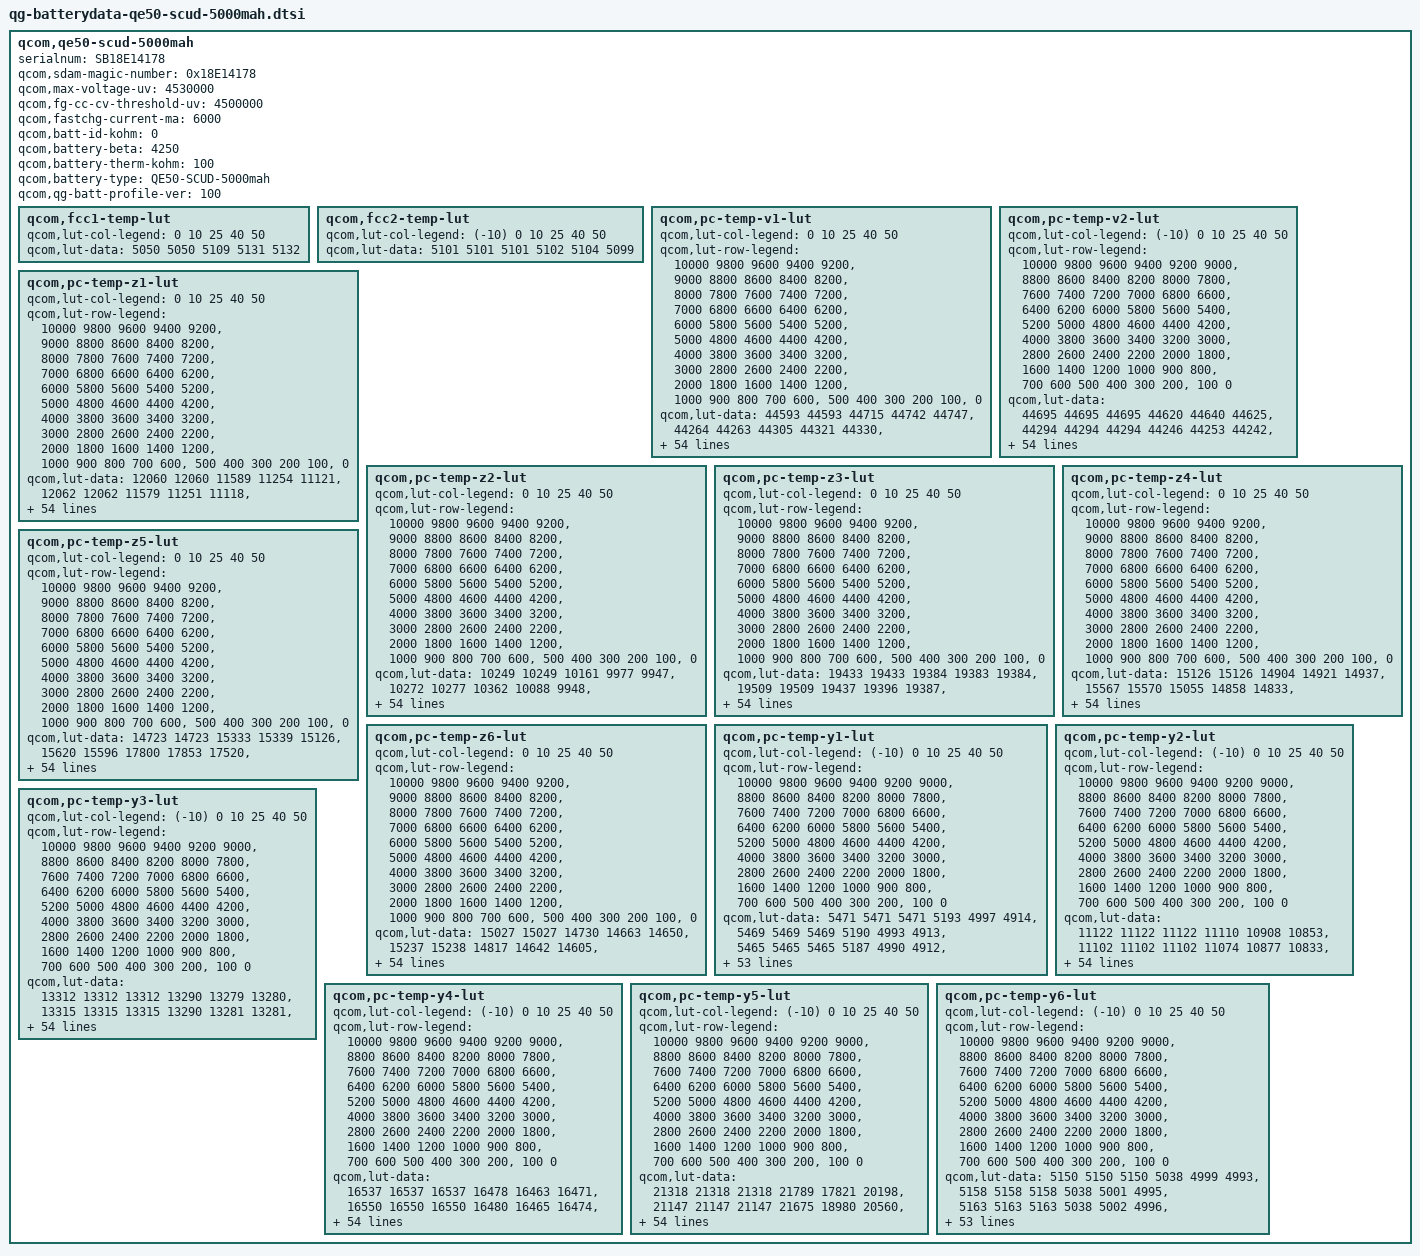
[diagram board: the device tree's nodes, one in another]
/* Copyright (c) 2018, The Linux Foundation. All rights reserved.
 *
 * This program is free software; you can redistribute it and/or modify
 * it under the terms of the GNU General Public License version 2 and
 * only version 2 as published by the Free Software Foundation.
 *
 * This program is distributed in the hope that it will be useful,
 * but WITHOUT ANY WARRANTY; without even the implied warranty of
 * MERCHANTABILITY or FITNESS FOR A PARTICULAR PURPOSE.  See the
 * GNU General Public License for more details.
 */

qcom,qe50-scud-5000mah {
    /* 6988512_Huaqin_QN6982A_5000mAH_averaged_MasterSlave_Jan24th2024 */
    serialnum = "SB18E14178";
    qcom,sdam-magic-number = <0x18E14178>;
    qcom,max-voltage-uv = <4530000>;
    qcom,fg-cc-cv-threshold-uv = <4500000>;
    qcom,fastchg-current-ma = <6000>;
    qcom,batt-id-kohm = <0>;
    qcom,battery-beta = <4250>;
    qcom,battery-therm-kohm = <100>;
    qcom,battery-type = "QE50-SCUD-5000mah";
    qcom,qg-batt-profile-ver = <100>;

	qcom,fcc1-temp-lut {
		qcom,lut-col-legend = <0 10 25 40 50>;
		qcom,lut-data = <5050 5050 5109 5131 5132>;
	};

	qcom,fcc2-temp-lut {
		qcom,lut-col-legend = <(-10) 0 10 25 40 50>;
		qcom,lut-data = <5101 5101 5101 5102 5104 5099>;
	};

	qcom,pc-temp-v1-lut {
		qcom,lut-col-legend = <0 10 25 40 50>;
		qcom,lut-row-legend = <10000 9800 9600 9400 9200>,
			<9000 8800 8600 8400 8200>,
			<8000 7800 7600 7400 7200>,
			<7000 6800 6600 6400 6200>,
			<6000 5800 5600 5400 5200>,
			<5000 4800 4600 4400 4200>,
			<4000 3800 3600 3400 3200>,
			<3000 2800 2600 2400 2200>,
			<2000 1800 1600 1400 1200>,
			<1000 900 800 700 600>,
			<500 400 300 200 100>,
			<0>;
		qcom,lut-data = <44593 44593 44715 44742 44747>,
			<44264 44263 44305 44321 44330>,
			<44034 44033 44047 44043 44049>,
			<43818 43818 43831 43825 43822>,
			<43593 43593 43611 43606 43601>,
			<43369 43369 43390 43385 43382>,
			<43135 43135 43164 43159 43160>,
			<42893 42893 42925 42924 42926>,
			<42647 42647 42679 42680 42683>,
			<42400 42400 42432 42436 42440>,
			<42152 42152 42183 42187 42198>,
			<41911 41911 41938 41943 41958>,
			<41676 41676 41697 41704 41719>,
			<41446 41446 41462 41469 41483>,
			<41221 41221 41238 41242 41253>,
			<41003 41003 41023 41019 41027>,
			<40795 40795 40814 40806 40810>,
			<40596 40596 40608 40602 40603>,
			<40407 40407 40410 40407 40406>,
			<40232 40232 40230 40228 40223>,
			<40059 40059 40062 40062 40058>,
			<39873 39873 39876 39871 39871>,
			<39680 39680 39659 39622 39622>,
			<39470 39470 39438 39374 39370>,
			<39211 39211 39225 39184 39187>,
			<38980 38980 39023 39023 39038>,
			<38855 38855 38881 38889 38905>,
			<38769 38769 38783 38780 38782>,
			<38685 38685 38694 38681 38672>,
			<38597 38597 38600 38583 38576>,
			<38514 38514 38510 38491 38491>,
			<38439 38439 38428 38410 38411>,
			<38370 38370 38353 38338 38337>,
			<38308 38308 38285 38270 38265>,
			<38254 38254 38228 38205 38196>,
			<38205 38205 38174 38142 38128>,
			<38161 38161 38120 38077 38059>,
			<38119 38119 38066 38013 37989>,
			<38064 38064 38001 37935 37904>,
			<37988 37988 37919 37829 37784>,
			<37894 37894 37819 37710 37648>,
			<37778 37778 37705 37597 37528>,
			<37636 37636 37570 37478 37408>,
			<37469 37469 37407 37314 37243>,
			<37306 37306 37246 37161 37091>,
			<37174 37174 37129 37069 37006>,
			<37127 37127 37088 37039 36982>,
			<37102 37101 37059 37014 36961>,
			<37072 37072 37032 36989 36934>,
			<37038 37038 36999 36951 36889>,
			<36914 36914 36854 36751 36669>,
			<36515 36515 36439 36333 36241>,
			<35917 35917 35854 35760 35667>,
			<35071 35071 35052 34975 34881>,
			<33684 33684 33799 33761 33662>,
			<30000 30000 30000 30000 30000>;
	};

	qcom,pc-temp-v2-lut {
		qcom,lut-col-legend = <(-10) 0 10 25 40 50>;
		qcom,lut-row-legend = <10000 9800 9600 9400 9200 9000>,
			<8800 8600 8400 8200 8000 7800>,
			<7600 7400 7200 7000 6800 6600>,
			<6400 6200 6000 5800 5600 5400>,
			<5200 5000 4800 4600 4400 4200>,
			<4000 3800 3600 3400 3200 3000>,
			<2800 2600 2400 2200 2000 1800>,
			<1600 1400 1200 1000 900 800>,
			<700 600 500 400 300 200>,
			<100 0>;
		qcom,lut-data = <44695 44695 44695 44620 44640 44625>,
			<44294 44294 44294 44246 44253 44242>,
			<43951 43951 43951 43921 43919 43911>,
			<43681 43681 43681 43656 43652 43644>,
			<43468 43468 43468 43441 43439 43429>,
			<43254 43254 43254 43224 43224 43213>,
			<43021 43021 43021 42989 42992 42982>,
			<42782 42782 42782 42750 42755 42747>,
			<42537 42537 42537 42507 42511 42507>,
			<42285 42285 42285 42259 42260 42262>,
			<42036 42036 42036 42013 42012 42018>,
			<41792 41792 41792 41770 41771 41776>,
			<41551 41551 41551 41530 41534 41537>,
			<41314 41314 41314 41296 41300 41302>,
			<41082 41082 41082 41067 41071 41073>,
			<40859 40859 40859 40846 40850 40852>,
			<40643 40643 40643 40633 40637 40637>,
			<40437 40437 40437 40428 40433 40431>,
			<40253 40253 40253 40235 40240 40235>,
			<40076 40076 40076 40050 40055 40048>,
			<39863 39863 39863 39859 39876 39869>,
			<39594 39594 39594 39666 39707 39706>,
			<39334 39334 39334 39461 39522 39527>,
			<39112 39112 39112 39216 39270 39280>,
			<38913 38913 38913 38966 39001 39011>,
			<38747 38747 38747 38785 38815 38824>,
			<38604 38604 38604 38647 38680 38690>,
			<38477 38477 38477 38528 38562 38572>,
			<38362 38362 38362 38420 38451 38458>,
			<38258 38258 38258 38323 38351 38355>,
			<38162 38162 38162 38232 38263 38264>,
			<38073 38073 38073 38147 38184 38182>,
			<37994 37994 37994 38070 38109 38107>,
			<37923 37923 37923 38002 38040 38043>,
			<37858 37858 37858 37935 37972 37980>,
			<37805 37805 37805 37862 37898 37897>,
			<37759 37759 37759 37786 37819 37799>,
			<37705 37705 37705 37706 37730 37694>,
			<37638 37638 37638 37626 37626 37584>,
			<37558 37558 37558 37540 37517 37473>,
			<37460 37460 37460 37448 37423 37376>,
			<37340 37340 37340 37345 37328 37279>,
			<37197 37197 37197 37220 37213 37166>,
			<37033 37033 37033 37078 37070 37024>,
			<36843 36843 36843 36942 36933 36882>,
			<36734 36734 36734 36864 36870 36824>,
			<36688 36688 36688 36850 36857 36812>,
			<36641 36641 36641 36833 36843 36798>,
			<36581 36581 36581 36808 36822 36775>,
			<36485 36485 36485 36744 36774 36717>,
			<36254 36254 36254 36513 36557 36467>,
			<35705 35705 35705 36021 36085 35992>,
			<34900 34900 34900 35344 35451 35349>,
			<33903 33903 33903 34392 34563 34450>,
			<32653 32653 32653 33093 33222 33072>,
			<28765 28765 28765 28469 28654 28712>;
	};

	qcom,pc-temp-z1-lut {
		qcom,lut-col-legend = <0 10 25 40 50>;
		qcom,lut-row-legend = <10000 9800 9600 9400 9200>,
			<9000 8800 8600 8400 8200>,
			<8000 7800 7600 7400 7200>,
			<7000 6800 6600 6400 6200>,
			<6000 5800 5600 5400 5200>,
			<5000 4800 4600 4400 4200>,
			<4000 3800 3600 3400 3200>,
			<3000 2800 2600 2400 2200>,
			<2000 1800 1600 1400 1200>,
			<1000 900 800 700 600>,
			<500 400 300 200 100>,
			<0>;
		qcom,lut-data = <12060 12060 11589 11254 11121>,
			<12062 12062 11579 11251 11118>,
			<12049 12049 11572 11239 11113>,
			<12035 12035 11559 11231 11106>,
			<12017 12017 11545 11224 11100>,
			<11994 11994 11530 11216 11095>,
			<11970 11970 11517 11209 11091>,
			<11944 11944 11506 11204 11087>,
			<11924 11924 11496 11201 11084>,
			<11910 11910 11491 11197 11082>,
			<11900 11900 11488 11195 11080>,
			<11895 11895 11486 11192 11079>,
			<11890 11890 11481 11190 11078>,
			<11885 11885 11476 11188 11077>,
			<11881 11881 11474 11188 11076>,
			<11876 11876 11472 11189 11076>,
			<11875 11875 11472 11190 11075>,
			<11876 11876 11472 11188 11076>,
			<11877 11877 11472 11186 11076>,
			<11881 11881 11472 11186 11077>,
			<11885 11885 11472 11188 11078>,
			<11886 11886 11473 11189 11079>,
			<11886 11886 11474 11189 11079>,
			<11887 11887 11476 11188 11079>,
			<11898 11898 11479 11189 11079>,
			<11911 11911 11484 11192 11080>,
			<11912 11912 11488 11194 11082>,
			<11911 11911 11490 11196 11083>,
			<11911 11911 11494 11199 11085>,
			<11920 11920 11500 11202 11088>,
			<11930 11930 11507 11205 11092>,
			<11932 11932 11511 11209 11095>,
			<11932 11932 11513 11212 11098>,
			<11934 11934 11516 11216 11101>,
			<11941 11941 11521 11220 11104>,
			<11950 11950 11529 11226 11108>,
			<11956 11956 11535 11231 11112>,
			<11961 11961 11542 11236 11116>,
			<11968 11968 11549 11241 11120>,
			<11978 11978 11557 11245 11124>,
			<11988 11988 11565 11250 11127>,
			<12000 12000 11572 11255 11131>,
			<12015 12015 11580 11261 11135>,
			<12030 12030 11588 11266 11138>,
			<12033 12033 11600 11271 11142>,
			<12032 12032 11606 11273 11145>,
			<12052 12052 11602 11273 11144>,
			<12034 12034 11605 11274 11146>,
			<12049 12049 11613 11276 11148>,
			<12045 12045 11619 11282 11152>,
			<12063 12063 11637 11289 11159>,
			<12073 12073 11643 11298 11166>,
			<12100 12100 11660 11312 11179>,
			<12120 12120 11693 11333 11200>,
			<12120 12120 11693 11333 11200>,
			<12120 12120 11693 11333 11200>;
	};

	qcom,pc-temp-z2-lut {
		qcom,lut-col-legend = <0 10 25 40 50>;
		qcom,lut-row-legend = <10000 9800 9600 9400 9200>,
			<9000 8800 8600 8400 8200>,
			<8000 7800 7600 7400 7200>,
			<7000 6800 6600 6400 6200>,
			<6000 5800 5600 5400 5200>,
			<5000 4800 4600 4400 4200>,
			<4000 3800 3600 3400 3200>,
			<3000 2800 2600 2400 2200>,
			<2000 1800 1600 1400 1200>,
			<1000 900 800 700 600>,
			<500 400 300 200 100>,
			<0>;
		qcom,lut-data = <10249 10249 10161 9977 9947>,
			<10272 10277 10362 10088 9948>,
			<10322 10324 10364 10197 10022>,
			<10343 10343 10332 10196 10147>,
			<10322 10322 10297 10192 10197>,
			<10284 10284 10253 10182 10161>,
			<10256 10256 10214 10168 10125>,
			<10233 10233 10180 10140 10120>,
			<10215 10215 10154 10101 10105>,
			<10198 10198 10151 10092 10087>,
			<10186 10186 10163 10101 10042>,
			<10187 10187 10175 10110 10007>,
			<10201 10201 10183 10105 10005>,
			<10216 10216 10190 10091 10007>,
			<10228 10228 10310 10082 10014>,
			<10240 10240 10760 10059 10040>,
			<10250 10250 10977 10047 10061>,
			<10259 10259 10639 10042 10051>,
			<10267 10267 10245 10036 10030>,
			<10275 10275 10209 10037 10031>,
			<10284 10284 10208 10043 10041>,
			<10299 10299 10215 10062 10062>,
			<10321 10321 10271 10250 10265>,
			<10332 10332 10319 10441 10494>,
			<10334 10334 10296 10368 10435>,
			<10334 10334 10244 10158 10191>,
			<10327 10327 10227 10109 10113>,
			<10313 10313 10230 10288 10365>,
			<10307 10307 10235 10433 10595>,
			<10307 10307 10248 10366 10475>,
			<10308 10308 10263 10220 10187>,
			<10308 10308 10261 10128 10046>,
			<10309 10309 10235 10060 9981>,
			<10311 10311 10217 10027 9953>,
			<10319 10319 10213 10019 9956>,
			<10329 10329 10211 10016 9967>,
			<10340 10340 10220 10027 9987>,
			<10353 10353 10253 10067 10034>,
			<10364 10364 10279 10107 10083>,
			<10375 10375 10297 10144 10135>,
			<10382 10382 10310 10170 10175>,
			<10384 10384 10319 10172 10175>,
			<10385 10385 10324 10169 10165>,
			<10384 10384 10329 10181 10166>,
			<10415 10415 10336 10186 10169>,
			<10466 10466 10330 10188 10158>,
			<10460 10460 10309 10169 10135>,
			<10482 10480 10308 10181 10126>,
			<10529 10529 10313 10189 10150>,
			<10888 10887 10343 10242 10202>,
			<10869 10893 10348 10204 10172>,
			<10458 10459 10325 10114 10039>,
			<10377 10377 10301 10071 9986>,
			<10298 10298 10219 10023 9940>,
			<10298 10298 10219 10023 9940>,
			<10298 10298 10219 10023 9940>;
	};

	qcom,pc-temp-z3-lut {
		qcom,lut-col-legend = <0 10 25 40 50>;
		qcom,lut-row-legend = <10000 9800 9600 9400 9200>,
			<9000 8800 8600 8400 8200>,
			<8000 7800 7600 7400 7200>,
			<7000 6800 6600 6400 6200>,
			<6000 5800 5600 5400 5200>,
			<5000 4800 4600 4400 4200>,
			<4000 3800 3600 3400 3200>,
			<3000 2800 2600 2400 2200>,
			<2000 1800 1600 1400 1200>,
			<1000 900 800 700 600>,
			<500 400 300 200 100>,
			<0>;
		qcom,lut-data = <19433 19433 19384 19383 19384>,
			<19509 19509 19437 19396 19387>,
			<19522 19522 19444 19415 19407>,
			<19526 19526 19444 19415 19411>,
			<19528 19528 19443 19415 19413>,
			<19529 19530 19441 19419 19415>,
			<19529 19529 19439 19423 19416>,
			<19525 19525 19438 19421 19416>,
			<19521 19521 19437 19418 19415>,
			<19518 19518 19436 19415 19413>,
			<19514 19514 19433 19414 19409>,
			<19509 19509 19430 19412 19404>,
			<19500 19500 19427 19409 19401>,
			<19493 19493 19425 19405 19399>,
			<19490 19490 19425 19402 19397>,
			<19488 19488 19428 19398 19395>,
			<19485 19485 19429 19395 19392>,
			<19482 19482 19422 19392 19389>,
			<19479 19479 19412 19388 19385>,
			<19475 19475 19407 19383 19380>,
			<19472 19472 19403 19377 19373>,
			<19473 19473 19403 19375 19371>,
			<19476 19476 19410 19385 19376>,
			<19479 19479 19416 19395 19383>,
			<19482 19482 19412 19389 19378>,
			<19484 19484 19405 19373 19362>,
			<19482 19482 19403 19370 19358>,
			<19477 19477 19405 19395 19395>,
			<19475 19475 19408 19416 19429>,
			<19478 19478 19415 19416 19427>,
			<19481 19481 19423 19415 19416>,
			<19482 19482 19425 19412 19407>,
			<19482 19482 19423 19404 19399>,
			<19481 19481 19420 19395 19391>,
			<19479 19479 19415 19387 19382>,
			<19475 19475 19409 19379 19372>,
			<19473 19473 19404 19372 19364>,
			<19470 19470 19400 19365 19355>,
			<19467 19467 19397 19362 19351>,
			<19463 19463 19395 19365 19353>,
			<19459 19459 19394 19368 19356>,
			<19456 19456 19391 19366 19358>,
			<19453 19453 19387 19363 19360>,
			<19450 19450 19386 19365 19362>,
			<19438 19438 19384 19365 19362>,
			<19425 19425 19377 19360 19356>,
			<19425 19425 19374 19355 19353>,
			<19392 19403 19368 19345 19342>,
			<19368 19369 19366 19342 19336>,
			<19323 19323 19359 19333 19325>,
			<19327 19324 19361 19346 19332>,
			<19391 19390 19377 19359 19348>,
			<19424 19424 19379 19360 19350>,
			<19443 19443 19379 19362 19350>,
			<19443 19443 19379 19362 19350>,
			<19443 19443 19379 19362 19350>;
	};

	qcom,pc-temp-z4-lut {
		qcom,lut-col-legend = <0 10 25 40 50>;
		qcom,lut-row-legend = <10000 9800 9600 9400 9200>,
			<9000 8800 8600 8400 8200>,
			<8000 7800 7600 7400 7200>,
			<7000 6800 6600 6400 6200>,
			<6000 5800 5600 5400 5200>,
			<5000 4800 4600 4400 4200>,
			<4000 3800 3600 3400 3200>,
			<3000 2800 2600 2400 2200>,
			<2000 1800 1600 1400 1200>,
			<1000 900 800 700 600>,
			<500 400 300 200 100>,
			<0>;
		qcom,lut-data = <15126 15126 14904 14921 14937>,
			<15567 15570 15055 14858 14833>,
			<15325 15326 15043 14921 14908>,
			<15100 15100 14927 14857 14851>,
			<15000 15000 14859 14809 14806>,
			<14928 14928 14822 14782 14783>,
			<14875 14875 14793 14762 14765>,
			<14834 14834 14768 14745 14751>,
			<14802 14802 14748 14731 14740>,
			<14775 14775 14734 14724 14736>,
			<14753 14753 14723 14720 14735>,
			<14740 14740 14715 14717 14734>,
			<14731 14731 14710 14714 14731>,
			<14723 14723 14706 14711 14728>,
			<14717 14717 14697 14708 14724>,
			<14713 14713 14678 14705 14722>,
			<14709 14709 14669 14703 14719>,
			<14707 14707 14679 14700 14717>,
			<14704 14704 14690 14697 14715>,
			<14700 14700 14688 14691 14710>,
			<14697 14697 14682 14681 14697>,
			<14698 14698 14682 14679 14692>,
			<14708 14708 14702 14709 14725>,
			<14724 14724 14731 14752 14773>,
			<14775 14775 14766 14783 14799>,
			<14823 14823 14805 14811 14819>,
			<14820 14820 14811 14814 14820>,
			<14799 14799 14790 14769 14768>,
			<14779 14779 14765 14726 14717>,
			<14762 14762 14743 14714 14710>,
			<14747 14747 14723 14707 14707>,
			<14736 14736 14713 14701 14703>,
			<14728 14728 14707 14695 14697>,
			<14723 14723 14702 14690 14691>,
			<14719 14719 14698 14684 14684>,
			<14716 14716 14694 14679 14678>,
			<14713 14713 14690 14675 14674>,
			<14709 14709 14687 14672 14671>,
			<14705 14705 14686 14672 14670>,
			<14701 14701 14686 14681 14684>,
			<14695 14695 14686 14691 14701>,
			<14688 14688 14684 14689 14699>,
			<14678 14678 14678 14682 14690>,
			<14670 14670 14673 14684 14696>,
			<14657 14657 14663 14681 14698>,
			<14642 14642 14645 14655 14664>,
			<14638 14638 14641 14649 14655>,
			<14665 14652 14636 14644 14646>,
			<14684 14683 14625 14630 14631>,
			<14731 14731 14620 14617 14618>,
			<14724 14727 14623 14635 14654>,
			<14668 14668 14633 14662 14684>,
			<14643 14643 14640 14672 14697>,
			<14652 14652 14648 14677 14703>,
			<14652 14652 14648 14677 14703>,
			<14652 14652 14648 14677 14703>;
	};

	qcom,pc-temp-z5-lut {
		qcom,lut-col-legend = <0 10 25 40 50>;
		qcom,lut-row-legend = <10000 9800 9600 9400 9200>,
			<9000 8800 8600 8400 8200>,
			<8000 7800 7600 7400 7200>,
			<7000 6800 6600 6400 6200>,
			<6000 5800 5600 5400 5200>,
			<5000 4800 4600 4400 4200>,
			<4000 3800 3600 3400 3200>,
			<3000 2800 2600 2400 2200>,
			<2000 1800 1600 1400 1200>,
			<1000 900 800 700 600>,
			<500 400 300 200 100>,
			<0>;
		qcom,lut-data = <14723 14723 15333 15339 15126>,
			<15620 15596 17800 17853 17520>,
			<16709 16697 18072 18923 18117>,
			<17877 17878 19365 20293 21017>,
			<18936 18941 20156 21689 23402>,
			<19971 19979 20595 23202 24814>,
			<20875 20882 21066 24635 26080>,
			<21640 21644 21810 25753 27606>,
			<22495 22495 22731 26709 29261>,
			<23777 23776 23693 27613 29677>,
			<25097 25097 24872 28559 29047>,
			<25778 25778 26005 29287 28486>,
			<26140 26140 26872 29838 28764>,
			<26620 26620 27747 30286 29583>,
			<27640 27640 29680 30513 30587>,
			<28880 28880 33651 31541 32094>,
			<29798 29798 35411 32209 33462>,
			<30539 30539 33522 32666 34346>,
			<31236 31236 31262 33233 35124>,
			<31887 31887 31003 33339 35906>,
			<32728 32728 31383 33364 36912>,
			<34937 34937 32337 33714 37950>,
			<39087 39087 36368 40690 41336>,
			<40773 40773 39682 47861 45007>,
			<39512 39513 35940 41779 40264>,
			<37268 37268 27689 25796 25284>,
			<34070 34066 24377 20982 20130>,
			<29715 29702 23270 23985 28941>,
			<28268 28253 22833 27629 37098>,
			<29448 29440 24823 30543 36829>,
			<31361 31360 28836 33072 35504>,
			<33576 33578 31863 33485 34878>,
			<36368 36368 34548 33244 34691>,
			<38360 38360 36035 33035 34448>,
			<39848 39848 36442 32694 33508>,
			<41130 41130 36733 32285 32096>,
			<42456 42456 37314 32282 31256>,
			<43818 43818 38196 32591 30557>,
			<44153 44153 38809 33244 30551>,
			<43890 43890 39199 37778 34313>,
			<43459 43459 39434 42474 38661>,
			<42620 42620 37990 39787 38263>,
			<41827 41827 34995 33587 36260>,
			<42045 42045 36281 36670 38895>,
			<40359 40359 39150 40422 41777>,
			<38031 38031 37650 38296 41191>,
			<38892 38892 34512 31252 34532>,
			<20589 23110 30161 24405 24367>,
			<15962 16019 32244 27414 25944>,
			<13046 13048 30265 28185 28365>,
			<13162 13053 30438 43929 33162>,
			<23729 23723 36887 27397 22087>,
			<31434 31435 33541 21834 18063>,
			<40625 40625 27548 18799 15647>,
			<40625 40625 27548 18799 15647>,
			<40625 40625 27548 18799 15647>;
	};

	qcom,pc-temp-z6-lut {
		qcom,lut-col-legend = <0 10 25 40 50>;
		qcom,lut-row-legend = <10000 9800 9600 9400 9200>,
			<9000 8800 8600 8400 8200>,
			<8000 7800 7600 7400 7200>,
			<7000 6800 6600 6400 6200>,
			<6000 5800 5600 5400 5200>,
			<5000 4800 4600 4400 4200>,
			<4000 3800 3600 3400 3200>,
			<3000 2800 2600 2400 2200>,
			<2000 1800 1600 1400 1200>,
			<1000 900 800 700 600>,
			<500 400 300 200 100>,
			<0>;
		qcom,lut-data = <15027 15027 14730 14663 14650>,
			<15237 15238 14817 14642 14605>,
			<15123 15123 14812 14678 14645>,
			<15013 15013 14757 14647 14622>,
			<14960 14960 14723 14626 14603>,
			<14919 14919 14702 14616 14594>,
			<14886 14886 14685 14607 14587>,
			<14857 14857 14672 14598 14581>,
			<14834 14834 14660 14590 14575>,
			<14813 14813 14651 14585 14570>,
			<14797 14797 14644 14582 14567>,
			<14783 14783 14638 14579 14564>,
			<14773 14773 14633 14575 14561>,
			<14765 14765 14630 14571 14558>,
			<14759 14759 14625 14568 14555>,
			<14755 14755 14620 14564 14553>,
			<14752 14752 14617 14561 14550>,
			<14749 14749 14615 14558 14547>,
			<14746 14746 14614 14555 14544>,
			<14742 14742 14611 14549 14539>,
			<14740 14740 14607 14542 14530>,
			<14741 14741 14606 14540 14526>,
			<14748 14748 14618 14559 14545>,
			<14759 14759 14634 14583 14569>,
			<14784 14784 14649 14591 14574>,
			<14806 14806 14662 14596 14575>,
			<14805 14805 14664 14596 14576>,
			<14795 14795 14657 14592 14574>,
			<14788 14788 14650 14586 14571>,
			<14784 14784 14645 14582 14567>,
			<14780 14780 14642 14578 14561>,
			<14777 14777 14639 14573 14555>,
			<14774 14774 14636 14568 14549>,
			<14772 14772 14634 14561 14542>,
			<14770 14770 14630 14555 14535>,
			<14768 14768 14626 14549 14527>,
			<14768 14768 14624 14544 14521>,
			<14767 14767 14621 14540 14515>,
			<14767 14767 14621 14538 14513>,
			<14766 14766 14622 14544 14520>,
			<14766 14766 14623 14550 14529>,
			<14765 14765 14622 14549 14529>,
			<14764 14764 14619 14545 14526>,
			<14765 14765 14619 14548 14530>,
			<14761 14761 14616 14547 14531>,
			<14753 14753 14607 14534 14514>,
			<14752 14752 14604 14529 14509>,
			<14747 14747 14599 14522 14500>,
			<14745 14745 14595 14514 14491>,
			<14746 14746 14591 14505 14479>,
			<14751 14751 14596 14520 14499>,
			<14766 14766 14613 14541 14524>,
			<14782 14782 14622 14549 14533>,
			<14809 14809 14633 14557 14542>,
			<14809 14809 14633 14557 14542>,
			<14809 14809 14633 14557 14542>;
	};

	qcom,pc-temp-y1-lut {
		qcom,lut-col-legend = <(-10) 0 10 25 40 50>;
		qcom,lut-row-legend = <10000 9800 9600 9400 9200 9000>,
			<8800 8600 8400 8200 8000 7800>,
			<7600 7400 7200 7000 6800 6600>,
			<6400 6200 6000 5800 5600 5400>,
			<5200 5000 4800 4600 4400 4200>,
			<4000 3800 3600 3400 3200 3000>,
			<2800 2600 2400 2200 2000 1800>,
			<1600 1400 1200 1000 900 800>,
			<700 600 500 400 300 200>,
			<100 0>;
		qcom,lut-data = <5471 5471 5471 5193 4997 4914>,
			<5469 5469 5469 5190 4993 4913>,
			<5465 5465 5465 5187 4990 4912>,
			<5461 5461 5461 5183 4987 4910>,
			<5457 5457 5457 5179 4984 4909>,
			<5455 5455 5455 5176 4982 4907>,
			<5451 5451 5451 5171 4980 4906>,
			<5449 5449 5449 5167 4978 4904>,
			<5449 5449 5449 5164 4975 4903>,
			<5453 5453 5453 5162 4973 4902>,
			<5454 5454 5454 5160 4972 4902>,
			<5448 5448 5448 5158 4970 4901>,
			<5441 5441 5441 5155 4969 4901>,
			<5440 5440 5440 5153 4968 4901>,
			<5441 5441 5441 5151 4967 4900>,
			<5441 5441 5441 5150 4967 4900>,
			<5441 5441 5441 5149 4967 4900>,
			<5441 5441 5441 5148 4967 4900>,
			<5439 5439 5439 5146 4967 4900>,
			<5436 5436 5436 5145 4967 4900>,
			<5437 5437 5437 5145 4968 4901>,
			<5444 5444 5444 5147 4969 4901>,
			<5449 5449 5449 5149 4969 4902>,
			<5446 5446 5446 5153 4970 4902>,
			<5442 5442 5442 5158 4971 4903>,
			<5443 5443 5443 5160 4972 4904>,
			<5450 5450 5450 5161 4974 4905>,
			<5455 5455 5455 5162 4976 4906>,
			<5456 5456 5456 5163 4978 4908>,
			<5455 5455 5455 5165 4980 4909>,
			<5456 5456 5456 5168 4982 4911>,
			<5460 5460 5460 5173 4984 4913>,
			<5461 5461 5461 5177 4986 4914>,
			<5458 5458 5458 5182 4988 4916>,
			<5455 5455 5455 5185 4990 4918>,
			<5458 5458 5458 5186 4992 4919>,
			<5469 5469 5469 5187 4993 4920>,
			<5474 5474 5474 5188 4994 4921>,
			<5474 5474 5474 5191 4995 4921>,
			<5475 5475 5475 5194 4995 4922>,
			<5477 5477 5477 5195 4997 4923>,
			<5482 5482 5482 5195 4998 4925>,
			<5489 5489 5489 5199 5000 4926>,
			<5493 5493 5493 5206 5002 4928>,
			<5496 5496 5496 5213 5006 4931>,
			<5503 5503 5503 5220 5010 4933>,
			<5500 5500 5500 5226 5009 4934>,
			<5526 5526 5526 5228 5009 4933>,
			<5512 5512 5512 5225 5009 4934>,
			<5511 5511 5511 5228 5010 4935>,
			<5565 5565 5565 5231 5012 4937>,
			<5585 5585 5585 5240 5017 4941>,
			<5655 5655 5655 5266 5024 4948>,
			<5692 5692 5692 5305 5034 4959>,
			<5692 5692 5692 5305 5034 4959>,
			<5692 5692 5692 5305 5034 4959>;
	};

	qcom,pc-temp-y2-lut {
		qcom,lut-col-legend = <(-10) 0 10 25 40 50>;
		qcom,lut-row-legend = <10000 9800 9600 9400 9200 9000>,
			<8800 8600 8400 8200 8000 7800>,
			<7600 7400 7200 7000 6800 6600>,
			<6400 6200 6000 5800 5600 5400>,
			<5200 5000 4800 4600 4400 4200>,
			<4000 3800 3600 3400 3200 3000>,
			<2800 2600 2400 2200 2000 1800>,
			<1600 1400 1200 1000 900 800>,
			<700 600 500 400 300 200>,
			<100 0>;
		qcom,lut-data = <11122 11122 11122 11110 10908 10853>,
			<11102 11102 11102 11074 10877 10833>,
			<11080 11080 11080 11035 10843 10812>,
			<11055 11055 11055 10997 10812 10790>,
			<11030 11030 11030 10963 10786 10769>,
			<11002 11002 11002 10937 10768 10748>,
			<10972 10972 10972 10916 10759 10727>,
			<10942 10942 10942 10897 10750 10707>,
			<10912 10912 10912 10875 10733 10687>,
			<10883 10883 10883 10843 10704 10667>,
			<10864 10864 10864 10820 10684 10654>,
			<10852 10852 10852 10807 10672 10642>,
			<10845 10845 10845 10796 10664 10630>,
			<10852 10852 10852 10790 10659 10618>,
			<10876 10876 10876 10784 10654 10600>,
			<10907 10907 10907 10783 10650 10592>,
			<10952 10952 10952 10803 10642 10587>,
			<11006 11006 11006 10836 10636 10584>,
			<11072 11072 11072 10884 10654 10588>,
			<11140 11140 11140 10952 10706 10599>,
			<11152 11152 11152 11015 10779 10628>,
			<11130 11130 11130 11085 10916 10755>,
			<11110 11110 11110 11122 11000 10846>,
			<11105 11105 11105 11085 10941 10841>,
			<11102 11102 11102 11020 10846 10830>,
			<11103 11103 11103 10997 10833 10827>,
			<11116 11116 11116 10987 10855 10828>,
			<11132 11132 11132 10987 10872 10830>,
			<11151 11151 11151 11010 10892 10848>,
			<11168 11168 11168 11045 10915 10879>,
			<11178 11178 11178 11071 10918 10910>,
			<11184 11184 11184 11095 10918 10948>,
			<11187 11187 11187 11114 10924 10969>,
			<11181 11181 11181 11132 10963 10980>,
			<11171 11171 11171 11145 11002 10986>,
			<11159 11159 11159 11140 10994 10984>,
			<11140 11140 11140 11123 10960 10970>,
			<11111 11111 11111 11112 10937 10956>,
			<11051 11051 11051 11110 10925 10944>,
			<10972 10972 10972 11108 10916 10933>,
			<10887 10887 10887 11088 10919 10904>,
			<10786 10786 10786 11063 10928 10861>,
			<10667 10667 10667 11070 10913 10853>,
			<10497 10497 10497 11035 10889 10836>,
			<10019 10019 10019 11002 10897 10777>,
			<9946 9946 9946 10936 10785 10661>,
			<9811 9811 9811 10934 10743 10641>,
			<9707 9707 9707 10955 10749 10638>,
			<9673 9673 9673 10994 10747 10674>,
			<9660 9660 9660 11017 10800 10632>,
			<9654 9654 9654 10960 10755 10683>,
			<9651 9651 9651 10858 10696 10596>,
			<9650 9650 9650 10759 10623 10512>,
			<9650 9650 9650 10618 10500 10378>,
			<9650 9650 9650 10618 10500 10378>,
			<9650 9650 9650 10618 10500 10378>;
	};

	qcom,pc-temp-y3-lut {
		qcom,lut-col-legend = <(-10) 0 10 25 40 50>;
		qcom,lut-row-legend = <10000 9800 9600 9400 9200 9000>,
			<8800 8600 8400 8200 8000 7800>,
			<7600 7400 7200 7000 6800 6600>,
			<6400 6200 6000 5800 5600 5400>,
			<5200 5000 4800 4600 4400 4200>,
			<4000 3800 3600 3400 3200 3000>,
			<2800 2600 2400 2200 2000 1800>,
			<1600 1400 1200 1000 900 800>,
			<700 600 500 400 300 200>,
			<100 0>;
		qcom,lut-data = <13312 13312 13312 13290 13279 13280>,
			<13315 13315 13315 13290 13281 13281>,
			<13317 13317 13317 13291 13283 13281>,
			<13319 13319 13319 13292 13284 13282>,
			<13321 13321 13321 13293 13286 13283>,
			<13323 13323 13323 13294 13287 13284>,
			<13324 13324 13324 13295 13287 13285>,
			<13326 13326 13326 13295 13288 13285>,
			<13327 13327 13327 13296 13288 13286>,
			<13327 13327 13327 13297 13288 13287>,
			<13328 13328 13328 13297 13288 13288>,
			<13329 13329 13329 13298 13289 13288>,
			<13331 13331 13331 13298 13290 13289>,
			<13331 13331 13331 13299 13290 13289>,
			<13330 13330 13330 13299 13291 13290>,
			<13330 13330 13330 13300 13291 13290>,
			<13327 13327 13327 13301 13292 13291>,
			<13324 13324 13324 13302 13293 13291>,
			<13324 13324 13324 13302 13294 13292>,
			<13324 13324 13324 13301 13296 13292>,
			<13323 13323 13323 13300 13297 13292>,
			<13319 13319 13319 13300 13295 13292>,
			<13314 13314 13314 13299 13293 13291>,
			<13311 13311 13311 13296 13289 13288>,
			<13309 13309 13309 13292 13284 13283>,
			<13308 13308 13308 13290 13283 13281>,
			<13306 13306 13306 13289 13283 13282>,
			<13305 13305 13305 13288 13282 13282>,
			<13305 13305 13305 13288 13282 13281>,
			<13304 13304 13304 13289 13281 13280>,
			<13303 13303 13303 13289 13281 13280>,
			<13303 13303 13303 13288 13281 13279>,
			<13302 13302 13302 13288 13281 13279>,
			<13302 13302 13302 13288 13281 13281>,
			<13302 13302 13302 13288 13282 13282>,
			<13302 13302 13302 13288 13282 13282>,
			<13303 13303 13303 13287 13283 13282>,
			<13305 13305 13305 13287 13283 13281>,
			<13306 13306 13306 13287 13283 13281>,
			<13308 13308 13308 13287 13282 13281>,
			<13310 13310 13310 13287 13283 13282>,
			<13313 13313 13313 13287 13284 13283>,
			<13317 13317 13317 13288 13283 13282>,
			<13322 13322 13322 13287 13282 13281>,
			<13318 13318 13318 13286 13280 13280>,
			<13337 13337 13337 13287 13284 13284>,
			<13357 13357 13357 13290 13287 13287>,
			<13406 13406 13406 13293 13289 13289>,
			<13517 13517 13517 13296 13291 13291>,
			<13878 13878 13878 13298 13292 13291>,
			<15122 15122 15122 13296 13288 13289>,
			<19825 19825 19825 13296 13288 13291>,
			<39264 39264 39264 13302 13292 13292>,
			<65535 65535 65535 13317 13298 13299>,
			<65535 65535 65535 13317 13298 13299>,
			<65535 65535 65535 13317 13298 13299>;
	};

	qcom,pc-temp-y4-lut {
		qcom,lut-col-legend = <(-10) 0 10 25 40 50>;
		qcom,lut-row-legend = <10000 9800 9600 9400 9200 9000>,
			<8800 8600 8400 8200 8000 7800>,
			<7600 7400 7200 7000 6800 6600>,
			<6400 6200 6000 5800 5600 5400>,
			<5200 5000 4800 4600 4400 4200>,
			<4000 3800 3600 3400 3200 3000>,
			<2800 2600 2400 2200 2000 1800>,
			<1600 1400 1200 1000 900 800>,
			<700 600 500 400 300 200>,
			<100 0>;
		qcom,lut-data = <16537 16537 16537 16478 16463 16471>,
			<16550 16550 16550 16480 16465 16474>,
			<16567 16567 16567 16481 16468 16478>,
			<16584 16584 16584 16482 16470 16481>,
			<16596 16596 16596 16482 16472 16484>,
			<16600 16600 16600 16482 16473 16485>,
			<16598 16598 16598 16480 16473 16485>,
			<16594 16594 16594 16479 16472 16484>,
			<16589 16589 16589 16478 16471 16483>,
			<16583 16583 16583 16478 16469 16481>,
			<16580 16580 16580 16478 16469 16480>,
			<16581 16581 16581 16480 16470 16480>,
			<16582 16582 16582 16484 16471 16479>,
			<16586 16586 16586 16488 16472 16479>,
			<16597 16597 16597 16493 16474 16479>,
			<16612 16612 16612 16500 16477 16479>,
			<16638 16638 16638 16509 16481 16481>,
			<16668 16668 16668 16520 16487 16483>,
			<16702 16702 16702 16543 16494 16487>,
			<16736 16736 16736 16574 16505 16495>,
			<16736 16736 16736 16594 16525 16511>,
			<16677 16677 16677 16608 16572 16556>,
			<16612 16612 16612 16615 16601 16585>,
			<16568 16568 16568 16569 16558 16551>,
			<16532 16532 16532 16492 16487 16490>,
			<16516 16516 16516 16471 16469 16473>,
			<16507 16507 16507 16466 16464 16469>,
			<16503 16503 16503 16465 16463 16468>,
			<16501 16501 16501 16467 16464 16469>,
			<16500 16500 16500 16471 16467 16470>,
			<16498 16498 16498 16474 16472 16472>,
			<16494 16494 16494 16478 16480 16479>,
			<16492 16492 16492 16483 16488 16489>,
			<16490 16490 16490 16489 16498 16508>,
			<16488 16488 16488 16494 16506 16524>,
			<16492 16492 16492 16492 16510 16525>,
			<16506 16506 16506 16486 16513 16523>,
			<16518 16518 16518 16482 16512 16520>,
			<16527 16527 16527 16478 16499 16510>,
			<16534 16534 16534 16476 16487 16501>,
			<16537 16537 16537 16480 16492 16507>,
			<16540 16540 16540 16485 16500 16519>,
			<16540 16540 16540 16483 16500 16517>,
			<16538 16538 16538 16476 16483 16497>,
			<16536 16536 16536 16454 16443 16446>,
			<16536 16536 16536 16462 16458 16474>,
			<16554 16554 16554 16481 16496 16518>,
			<16580 16580 16580 16510 16539 16563>,
			<16614 16614 16614 16550 16581 16605>,
			<16661 16661 16661 16581 16609 16630>,
			<16787 16787 16787 16550 16552 16543>,
			<18537 18537 18537 16512 16492 16496>,
			<37942 37942 37942 16527 16488 16495>,
			<65535 65535 65535 16571 16486 16489>,
			<65535 65535 65535 16571 16486 16489>,
			<65535 65535 65535 16571 16486 16489>;
	};

	qcom,pc-temp-y5-lut {
		qcom,lut-col-legend = <(-10) 0 10 25 40 50>;
		qcom,lut-row-legend = <10000 9800 9600 9400 9200 9000>,
			<8800 8600 8400 8200 8000 7800>,
			<7600 7400 7200 7000 6800 6600>,
			<6400 6200 6000 5800 5600 5400>,
			<5200 5000 4800 4600 4400 4200>,
			<4000 3800 3600 3400 3200 3000>,
			<2800 2600 2400 2200 2000 1800>,
			<1600 1400 1200 1000 900 800>,
			<700 600 500 400 300 200>,
			<100 0>;
		qcom,lut-data = <21318 21318 21318 21789 17821 20198>,
			<21147 21147 21147 21675 18980 20560>,
			<20963 20963 20963 21523 20343 20984>,
			<20797 20797 20797 21354 21654 21400>,
			<20679 20679 20679 21187 22657 21739>,
			<20640 20640 20640 21040 23099 21929>,
			<20680 20680 20680 20895 23147 22014>,
			<20730 20730 20730 20749 23034 22063>,
			<20612 20612 20612 20566 22288 22141>,
			<20115 20115 20115 20206 20359 22320>,
			<19618 19618 19618 19801 19439 22386>,
			<19224 19224 19224 19262 19633 22110>,
			<18785 18785 18785 18628 19847 21648>,
			<18120 18120 18120 17985 19462 21151>,
			<17259 17259 17259 17318 18653 20530>,
			<16630 16630 16630 16825 18111 19938>,
			<16124 16124 16124 16489 17694 19368>,
			<15843 15843 15843 16191 17370 18744>,
			<16662 16662 16662 15780 17046 17758>,
			<18751 18751 18751 15346 16631 16605>,
			<20574 20574 20574 15717 16577 16330>,
			<22311 22311 22311 19317 17005 16430>,
			<23572 23572 23572 22601 17720 16630>,
			<24247 24247 24247 23835 19750 18398>,
			<24692 24692 24692 24621 22326 21237>,
			<24734 24734 24734 24477 22710 22018>,
			<24500 24500 24500 23161 22242 22077>,
			<24380 24380 24380 22382 21591 21909>,
			<24564 24564 24564 22780 20299 20481>,
			<24923 24923 24923 23353 18920 18480>,
			<25481 25481 25481 23464 18548 17711>,
			<26385 26385 26385 23340 18389 17267>,
			<26761 26761 26761 23346 18362 17145>,
			<26179 26179 26179 24186 19122 18609>,
			<25413 25413 25413 25146 20474 20687>,
			<25131 25131 25131 25293 22354 21820>,
			<24927 24927 24927 25325 24855 22672>,
			<24867 24867 24867 25420 25708 23035>,
			<24612 24612 24612 25944 25297 23161>,
			<24345 24345 24345 26414 24849 23221>,
			<24200 24200 24200 25356 24370 22851>,
			<23885 23885 23885 23659 23809 22205>,
			<23382 23382 23382 24618 25123 24526>,
			<22677 22677 22677 24499 25307 25543>,
			<16192 16192 16192 24344 24286 23623>,
			<16776 16776 16776 21176 20120 18189>,
			<15582 15582 15582 21327 17305 15652>,
			<14911 14911 14911 20056 15651 14634>,
			<14617 14617 14617 19050 15209 14234>,
			<14374 14374 14374 18347 15173 13907>,
			<13341 13341 13341 18053 14792 14389>,
			<10101 10101 10101 19679 16430 15938>,
			<8963 8963 8963 19816 16606 14625>,
			<8809 8809 8809 20390 17609 15186>,
			<8809 8809 8809 20390 17609 15186>,
			<8809 8809 8809 20390 17609 15186>;
	};

	qcom,pc-temp-y6-lut {
		qcom,lut-col-legend = <(-10) 0 10 25 40 50>;
		qcom,lut-row-legend = <10000 9800 9600 9400 9200 9000>,
			<8800 8600 8400 8200 8000 7800>,
			<7600 7400 7200 7000 6800 6600>,
			<6400 6200 6000 5800 5600 5400>,
			<5200 5000 4800 4600 4400 4200>,
			<4000 3800 3600 3400 3200 3000>,
			<2800 2600 2400 2200 2000 1800>,
			<1600 1400 1200 1000 900 800>,
			<700 600 500 400 300 200>,
			<100 0>;
		qcom,lut-data = <5150 5150 5150 5038 4999 4993>,
			<5158 5158 5158 5038 5001 4995>,
			<5163 5163 5163 5038 5002 4996>,
			<5166 5166 5166 5038 5004 4998>,
			<5167 5167 5167 5038 5006 5000>,
			<5167 5167 5167 5038 5006 5001>,
			<5165 5165 5165 5038 5007 5001>,
			<5162 5162 5162 5037 5007 5001>,
			<5159 5159 5159 5037 5007 5001>,
			<5155 5155 5155 5037 5006 5002>,
			<5153 5153 5153 5037 5005 5002>,
			<5152 5152 5152 5037 5006 5002>,
			<5151 5151 5151 5038 5007 5002>,
			<5152 5152 5152 5039 5008 5003>,
			<5153 5153 5153 5041 5009 5003>,
			<5155 5155 5155 5043 5010 5003>,
			<5160 5160 5160 5046 5012 5004>,
			<5166 5166 5166 5050 5014 5005>,
			<5174 5174 5174 5057 5017 5007>,
			<5183 5183 5183 5065 5021 5009>,
			<5183 5183 5183 5070 5028 5014>,
			<5163 5163 5163 5073 5039 5026>,
			<5141 5141 5141 5074 5046 5034>,
			<5127 5127 5127 5060 5031 5022>,
			<5116 5116 5116 5035 5007 5000>,
			<5112 5112 5112 5028 5001 4994>,
			<5109 5109 5109 5026 4999 4993>,
			<5108 5108 5108 5025 4999 4993>,
			<5108 5108 5108 5026 4999 4993>,
			<5109 5109 5109 5028 5000 4993>,
			<5110 5110 5110 5030 5001 4993>,
			<5110 5110 5110 5031 5003 4995>,
			<5110 5110 5110 5033 5006 4998>,
			<5112 5112 5112 5035 5009 5004>,
			<5114 5114 5114 5037 5012 5010>,
			<5119 5119 5119 5037 5014 5011>,
			<5127 5127 5127 5035 5015 5010>,
			<5136 5136 5136 5034 5015 5009>,
			<5146 5146 5146 5034 5011 5006>,
			<5156 5156 5156 5034 5008 5004>,
			<5168 5168 5168 5035 5010 5006>,
			<5183 5183 5183 5037 5013 5010>,
			<5202 5202 5202 5038 5013 5009>,
			<5228 5228 5228 5037 5007 5002>,
			<5238 5238 5238 5031 4995 4988>,
			<5300 5300 5300 5037 5003 5000>,
			<5361 5361 5361 5046 5015 5015>,
			<5457 5457 5457 5057 5029 5030>,
			<5629 5629 5629 5071 5043 5043>,
			<5998 5998 5998 5081 5052 5050>,
			<7039 7039 7039 5072 5033 5024>,
			<11043 11043 11043 5065 5016 5013>,
			<30055 30055 30055 5081 5019 5014>,
			<65535 65535 65535 5122 5025 5019>,
			<65535 65535 65535 5122 5025 5019>,
			<65535 65535 65535 5122 5025 5019>;
	};

};
